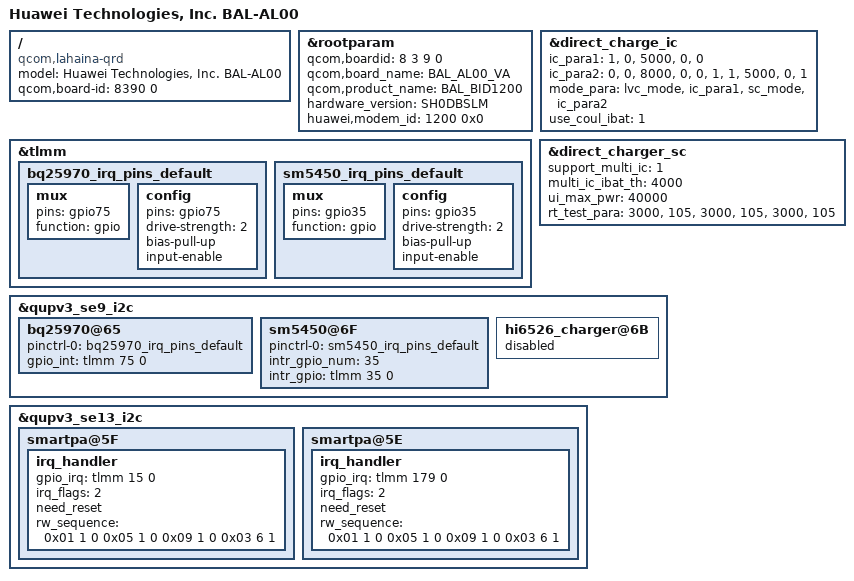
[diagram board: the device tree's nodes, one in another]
/dts-v1/;
/plugin/;

#include "../common/common.dtsi"
#include "huawei-nfc.dtsi"
#include "huawei_camera.dtsi"
#include "huawei_wifi.dtsi"
#include "huawei-lcd.dtsi"
#include "huawei-bt.dtsi"


/ {
    /* bsp_replace_info @ model = "Huawei Technologies, Inc. %product_name%"; */
    model = "Huawei Technologies, Inc. BAL-AL00";
    compatible = "qcom,lahaina-qrd", "qcom,lahaina", "qcom,qrd";
    /* bsp_replace_info @ qcom,board-id = <%boardid% 0>; */
    qcom,board-id = <8390 0>;
};

&rootparam {
    /* bsp_replace_info @ qcom,boardid = <%boardid_split%>; */
    /* auto_key_info @ name: boardid type: uint32 default: 0 */
    qcom,boardid = <8 3 9 0>;
    /* bsp_replace_info @ qcom,board_name = "%board_name%"; */
    qcom,board_name = "BAL_AL00_VA";
    /* bsp_replace_info @ qcom,product_name = "%product_name%"; */
    qcom,product_name = "BAL_BID1200";
    /* bsp_replace_info @ hardware_version = "%hardware_version%"; */
    hardware_version = "SH0DBSLM";
    /* bsp_replace_info @ huawei,modem_id = <%modem_id% 0x0>; */
    huawei,modem_id = <1200 0x0>;
};

&tlmm {
	bq25970_irq_pins_default: bq25970_irq_pins_default {
		mux {
			pins = "gpio75";
			function = "gpio";
		};
		config {
			pins = "gpio75";
			drive-strength = <2>;
			bias-pull-up;
			input-enable;
		};
	};

	sm5450_irq_pins_default: sm5450_irq_pins_default {
		mux {
			pins = "gpio35";
			function = "gpio";
		};
		config {
			pins = "gpio35";
			drive-strength = <2>;
			bias-pull-up;
			input-enable;
		};
	};
};

&direct_charge_ic {
	/* The IC_PARA table is used to find the relationship between chip and path */
	/* the chip's current passing capacity */
	/* and the sampling points of battery voltage and current */
	/* ic_index path_index max_ibat ibat_sample_point vbat_sample_point */
	/* ic_index  path_index  max_ibat  ibat_sample_point  vbat_sample_point */
	ic_para1 =
		"1", "0", "5000", "0", "0";
	ic_para2 =
		"0", "0", "8000", "0", "0",
		"1", "1", "5000", "0", "1";
	mode_para =
		"lvc_mode", "ic_para1",
		"sc_mode", "ic_para2";
	use_coul_ibat = <1>;
	status = "ok";
};

&direct_charger_sc {
	support_multi_ic = <1>;
	multi_ic_ibat_th = <4000>;
	ui_max_pwr = <40000>;
	rt_test_para =
		/* first:sc second:mainsc third:auxsc */
		"3000", "105",
		"3000", "105",
		"3000", "105";
};

&qupv3_se9_i2c {
	status = "ok";
	bq25970@65 {
		status = "ok";
		pinctrl-names = "default";
		pinctrl-0 = <&bq25970_irq_pins_default>;
		gpio_int = <&tlmm 75 0>;
	};

	sm5450@6F{
		status = "ok";
		pinctrl-names = "default";
		pinctrl-0 = <&sm5450_irq_pins_default>;
		intr_gpio_num = <35>; /* direct defined GPIO num */
		intr_gpio = <&tlmm 35 0>;
	};

	hi6526_charger@6B {
		status = "disabled";
	};
};

&qupv3_se13_i2c {
	#address-cells = <1>;
	#size-cells = <0>;
	status = "ok";

	smartpa@5F{
		irq_handler {
			gpio_irq = <&tlmm 15 0>; // GPIO_015
			/* 0x0 IRQF_TRIGGER_NONE, 0x1 IRQF_TRIGGER_RISING, 0x2 IRQF_TRIGGER_FALLING, 0x4 IRQF_TRIGGER_HIGH, 0x8 IRQF_TRIGGER_LOW */
			irq_flags = <2>;
			/* whether or not need reset chip */
			need_reset;
			rw_sequence = <
				0x01 1 0
				0x05 1 0
				0x09 1 0
				0x03 6 1 // mute chip
			>;
		};
	};

	smartpa@5E{
		irq_handler {
			gpio_irq = <&tlmm 179 0>; // GPIO_179
			/* 0x0 IRQF_TRIGGER_NONE, 0x1 IRQF_TRIGGER_RISING, 0x2 IRQF_TRIGGER_FALLING, 0x4 IRQF_TRIGGER_HIGH, 0x8 IRQF_TRIGGER_LOW */
			irq_flags = <2>;
			/* whether or not need reset chip */
			need_reset;
			rw_sequence = <
				0x01 1 0
				0x05 1 0
				0x09 1 0
				0x03 6 1 // mute chip
			>;
		};
	};
};
